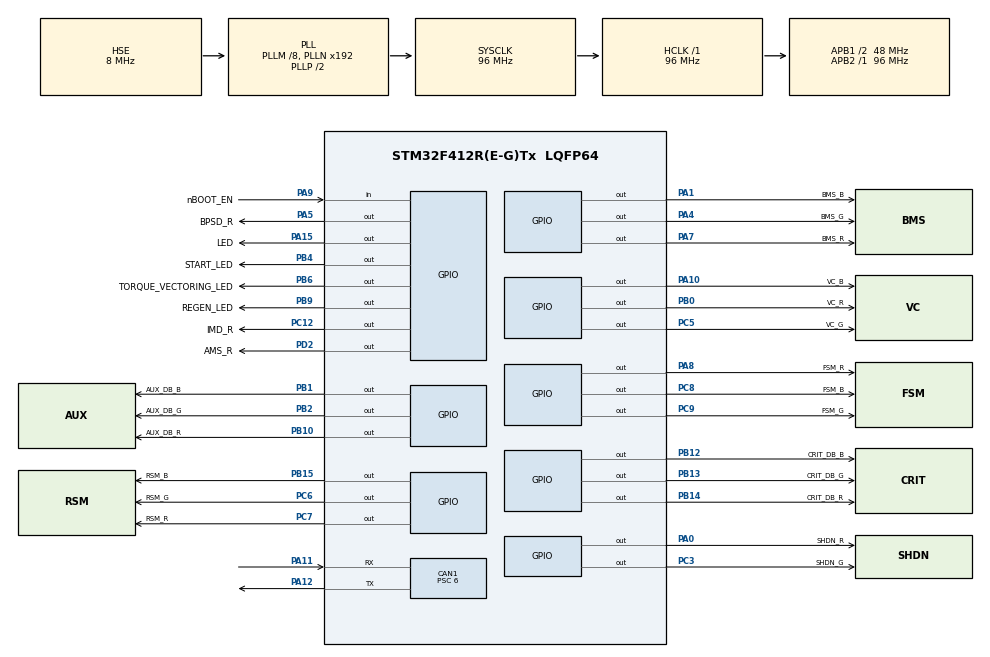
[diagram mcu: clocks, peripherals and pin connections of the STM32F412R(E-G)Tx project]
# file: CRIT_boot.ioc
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CAN1.ABOM=ENABLE
CAN1.BS1=CAN_BS1_13TQ
CAN1.BS2=CAN_BS2_2TQ
CAN1.CalculateBaudRate=500000
CAN1.CalculateTimeBit=2000
CAN1.CalculateTimeQuantum=125.0
CAN1.NART=ENABLE
CAN1.Prescaler=6
CAN1.RFLM=ENABLE
CAN1.SJW=CAN_SJW_4TQ
CAN1.TXFP=ENABLE
FREERTOS.Tasks01=interfaceTask,32,512,runInterfaceTask,Default,NULL,Static,interfaceTaskBuffer,interfaceTaskControlBlock;canTxTask,16,512,runCanTxTask,Default,NULL,Static,canTxTaskBuffer,canTxTaskControlBlock;tickTask,24,512,runTickTask,Default,NULL,Static,tickTaskBuffer,tickTaskControlBlock
FREERTOS.configUSE_NEWLIB_REENTRANT=1
Mcu.Family=STM32F4
Mcu.Name=STM32F412R(E-G)Tx
Mcu.Package=LQFP64
NVIC.CAN1_RX0_IRQn=true\:5\:0\:false\:false\:true\:true\:true\:true\:true
NVIC.CAN1_RX1_IRQn=true\:5\:0\:false\:false\:true\:true\:true\:true\:true
NVIC.PriorityGroup=NVIC_PRIORITYGROUP_4
NVIC.TIM6_IRQn=true\:15\:0\:false\:false\:true\:false\:false\:true\:true
NVIC.TimeBase=TIM6_IRQn
NVIC.TimeBaseIP=TIM6
PA0.GPIO_Label=SHDN_R
PA0.Signal=GPIO_Output
PA1.GPIO_Label=BMS_B
PA1.Signal=GPIO_Output
PA10.GPIO_Label=VC_B
PA10.Signal=GPIO_Output
PA11.Mode=CAN_Activate
PA11.Signal=CAN1_RX
PA12.Mode=CAN_Activate
PA12.Signal=CAN1_TX
PA13.Mode=Trace_Asynchronous_SW
PA13.Signal=SYS_JTMS-SWDIO
PA14.Mode=Trace_Asynchronous_SW
PA14.Signal=SYS_JTCK-SWCLK
PA15.GPIO_Label=LED
PA15.Signal=GPIO_Output
PA4.GPIO_Label=BMS_G
PA4.Signal=GPIO_Output
PA5.GPIO_Label=BPSD_R
PA5.Signal=GPIO_Output
PA7.GPIO_Label=BMS_R
PA7.Signal=GPIO_Output
PA8.GPIO_Label=FSM_R
PA8.Signal=GPIO_Output
PA9.GPIO_Label=nBOOT_EN
PA9.GPIO_PuPd=GPIO_PULLUP
PA9.Signal=GPIO_Input
PB0.GPIO_Label=VC_R
PB0.Signal=GPIO_Output
PB1.GPIO_Label=AUX_DB_B
PB1.Signal=GPIO_Output
PB10.GPIO_Label=AUX_DB_R
PB10.Signal=GPIO_Output
PB12.GPIO_Label=CRIT_DB_B
PB12.Signal=GPIO_Output
PB13.GPIO_Label=CRIT_DB_G
PB13.Signal=GPIO_Output
PB14.GPIO_Label=CRIT_DB_R
PB14.Signal=GPIO_Output
PB15.GPIO_Label=RSM_B
PB15.Signal=GPIO_Output
PB2.GPIO_Label=AUX_DB_G
PB2.Signal=GPIO_Output
PB3.Mode=Trace_Asynchronous_SW
PB3.Signal=SYS_JTDO-SWO
PB4.GPIO_Label=START_LED
PB4.Signal=GPIO_Output
PB6.GPIO_Label=TORQUE_VECTORING_LED
PB6.Signal=GPIO_Output
PB9.GPIO_Label=REGEN_LED
PB9.Signal=GPIO_Output
PC12.GPIO_Label=IMD_R
PC12.Signal=GPIO_Output
PC3.GPIO_Label=SHDN_G
PC3.Signal=GPIO_Output
PC5.GPIO_Label=VC_G
PC5.Signal=GPIO_Output
PC6.GPIO_Label=RSM_G
PC6.Signal=GPIO_Output
PC7.GPIO_Label=RSM_R
PC7.Signal=GPIO_Output
PC8.GPIO_Label=FSM_B
PC8.Signal=GPIO_Output
PC9.GPIO_Label=FSM_G
PC9.Signal=GPIO_Output
PD2.GPIO_Label=AMS_R
PD2.Signal=GPIO_Output
PH0\ -\ OSC_IN.Mode=HSE-External-Oscillator
PH0\ -\ OSC_IN.Signal=RCC_OSC_IN
PH1\ -\ OSC_OUT.Mode=HSE-External-Oscillator
PH1\ -\ OSC_OUT.Signal=RCC_OSC_OUT
ProjectManager.HeapSize=0x00
ProjectManager.StackSize=0x400
ProjectManager.TargetToolchain=STM32CubeIDE
RCC.AHBFreq_Value=96000000
RCC.APB1CLKDivider=RCC_HCLK_DIV2
RCC.APB1Freq_Value=48000000
RCC.APB1TimFreq_Value=96000000
RCC.APB2Freq_Value=96000000
RCC.APB2TimFreq_Value=96000000
RCC.CortexFreq_Value=96000000
RCC.HCLKFreq_Value=96000000
RCC.HSE_VALUE=8000000
RCC.PLLM=8
RCC.PLLSourceVirtual=RCC_PLLSOURCE_HSE
RCC.SYSCLKFreq_VALUE=96000000
RCC.SYSCLKSource=RCC_SYSCLKSOURCE_PLLCLK
RCC.USBFreq_Value=96000000
RCC.VCOOutputFreq_Value=192000000
VP_CRC_VS_CRC.Mode=CRC_Activate
VP_FREERTOS_VS_CMSIS_V2.Mode=CMSIS_V2
VP_SYS_VS_tim6.Mode=TIM6
board=custom

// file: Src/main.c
/* USER CODE BEGIN Header */
/**
 ******************************************************************************
 * @file           : main.c
 * @brief          : Main program body
 ******************************************************************************
 * @attention
 *
 * Copyright (c) 2023 STMicroelectronics.
 * All rights reserved.
 *
 * This software is licensed under terms that can be found in the LICENSE file
 * in the root directory of this software component.
 * If no LICENSE file comes with this software, it is provided AS-IS.
 *
 ******************************************************************************
 */
/* USER CODE END Header */
#include "main.h"
#include "cmsis_os.h"

/* USER CODE BEGIN Includes */
#include "bootloader.h"
#include "hw_can.h"
#include "hw_error.h"
#include "hw_utils.h"
#include "io_canQueue.h"

#include <assert.h>
/* USER CODE END Includes */

typedef StaticTask_t osStaticThreadDef_t;

CAN_HandleTypeDef hcan1;

CRC_HandleTypeDef hcrc;

/* Definitions for interfaceTask */
osThreadId_t         interfaceTaskHandle;
uint32_t             interfaceTaskBuffer[512];
osStaticThreadDef_t  interfaceTaskControlBlock;
const osThreadAttr_t interfaceTask_attributes = {
    .name       = "interfaceTask",
    .cb_mem     = &interfaceTaskControlBlock,
    .cb_size    = sizeof(interfaceTaskControlBlock),
    .stack_mem  = &interfaceTaskBuffer[0],
    .stack_size = sizeof(interfaceTaskBuffer),
    .priority   = (osPriority_t)osPriorityAboveNormal,
};
/* Definitions for canTxTask */
osThreadId_t         canTxTaskHandle;
uint32_t             canTxTaskBuffer[512];
osStaticThreadDef_t  canTxTaskControlBlock;
const osThreadAttr_t canTxTask_attributes = {
    .name       = "canTxTask",
    .cb_mem     = &canTxTaskControlBlock,
    .cb_size    = sizeof(canTxTaskControlBlock),
    .stack_mem  = &canTxTaskBuffer[0],
    .stack_size = sizeof(canTxTaskBuffer),
    .priority   = (osPriority_t)osPriorityBelowNormal,
};
/* Definitions for tickTask */
osThreadId_t         tickTaskHandle;
uint32_t             tickTaskBuffer[512];
osStaticThreadDef_t  tickTaskControlBlock;
const osThreadAttr_t tickTask_attributes = {
    .name       = "tickTask",
    .cb_mem     = &tickTaskControlBlock,
    .cb_size    = sizeof(tickTaskControlBlock),
    .stack_mem  = &tickTaskBuffer[0],
    .stack_size = sizeof(tickTaskBuffer),
    .priority   = (osPriority_t)osPriorityNormal,
};
/* USER CODE BEGIN PV */
CanHandle can = { .hcan = &hcan1, .bus_num = 1, .receive_callback = io_canQueue_pushRx };
/* USER CODE END PV */

void        SystemClock_Config(void);
static void MX_GPIO_Init(void);
static void MX_CAN1_Init(void);
static void MX_CRC_Init(void);
void        runInterfaceTask(void *argument);
void        runCanTxTask(void *argument);
void        runTickTask(void *argument);

int main(void)
{
    /* USER CODE BEGIN 1 */
    bootloader_preInit();
    /* USER CODE END 1 */

    /* MCU Configuration--------------------------------------------------------*/

    /* Reset of all peripherals, Initializes the Flash interface and the Systick. */
    HAL_Init();

    /* Configure the system clock */
    SystemClock_Config();

    /* Initialize all configured peripherals */
    MX_GPIO_Init();
    MX_CAN1_Init();
    MX_CRC_Init();
    /* USER CODE BEGIN 2 */
    bootloader_init();
    /* USER CODE END 2 */

    /* Init scheduler */
    osKernelInitialize();

    /* Create the thread(s) */
    /* creation of interfaceTask */
    interfaceTaskHandle = osThreadNew(runInterfaceTask, NULL, &interfaceTask_attributes);

    /* creation of canTxTask */
    canTxTaskHandle = osThreadNew(runCanTxTask, NULL, &canTxTask_attributes);

    /* creation of tickTask */
    tickTaskHandle = osThreadNew(runTickTask, NULL, &tickTask_attributes);

    /* Start scheduler */
    osKernelStart();

    /* We should never get here as control is now taken by the scheduler */
    /* Infinite loop */
    while (1)
    {

    }
}

void SystemClock_Config(void)
{
    RCC_OscInitTypeDef RCC_OscInitStruct = { 0 };
    RCC_ClkInitTypeDef RCC_ClkInitStruct = { 0 };

    /** Configure the main internal regulator output voltage
     */
    __HAL_RCC_PWR_CLK_ENABLE();
    __HAL_PWR_VOLTAGESCALING_CONFIG(PWR_REGULATOR_VOLTAGE_SCALE1);

    /** Initializes the RCC Oscillators according to the specified parameters
     * in the RCC_OscInitTypeDef structure.
     */
    RCC_OscInitStruct.OscillatorType = RCC_OSCILLATORTYPE_HSE;
    RCC_OscInitStruct.HSEState       = RCC_HSE_ON;
    RCC_OscInitStruct.PLL.PLLState   = RCC_PLL_ON;
    RCC_OscInitStruct.PLL.PLLSource  = RCC_PLLSOURCE_HSE;
    RCC_OscInitStruct.PLL.PLLM       = 8;
    RCC_OscInitStruct.PLL.PLLN       = 192;
    RCC_OscInitStruct.PLL.PLLP       = RCC_PLLP_DIV2;
    RCC_OscInitStruct.PLL.PLLQ       = 2;
    RCC_OscInitStruct.PLL.PLLR       = 2;
    if (HAL_RCC_OscConfig(&RCC_OscInitStruct) != HAL_OK)
    {
        Error_Handler();
    }

    /** Initializes the CPU, AHB and APB buses clocks
     */
    RCC_ClkInitStruct.ClockType = RCC_CLOCKTYPE_HCLK | RCC_CLOCKTYPE_SYSCLK | RCC_CLOCKTYPE_PCLK1 | RCC_CLOCKTYPE_PCLK2;
    RCC_ClkInitStruct.SYSCLKSource   = RCC_SYSCLKSOURCE_PLLCLK;
    RCC_ClkInitStruct.AHBCLKDivider  = RCC_SYSCLK_DIV1;
    RCC_ClkInitStruct.APB1CLKDivider = RCC_HCLK_DIV2;
    RCC_ClkInitStruct.APB2CLKDivider = RCC_HCLK_DIV1;

    if (HAL_RCC_ClockConfig(&RCC_ClkInitStruct, FLASH_LATENCY_3) != HAL_OK)
    {
        Error_Handler();
    }
}

static void MX_CAN1_Init(void)
{

    hcan1.Instance                  = CAN1;
    hcan1.Init.Prescaler            = 6;
    hcan1.Init.Mode                 = CAN_MODE_NORMAL;
    hcan1.Init.SyncJumpWidth        = CAN_SJW_4TQ;
    hcan1.Init.TimeSeg1             = CAN_BS1_13TQ;
    hcan1.Init.TimeSeg2             = CAN_BS2_2TQ;
    hcan1.Init.TimeTriggeredMode    = DISABLE;
    hcan1.Init.AutoBusOff           = ENABLE;
    hcan1.Init.AutoWakeUp           = DISABLE;
    hcan1.Init.AutoRetransmission   = ENABLE;
    hcan1.Init.ReceiveFifoLocked    = ENABLE;
    hcan1.Init.TransmitFifoPriority = ENABLE;
    if (HAL_CAN_Init(&hcan1) != HAL_OK)
    {
        Error_Handler();
    }
}

static void MX_CRC_Init(void)
{

    hcrc.Instance = CRC;
    if (HAL_CRC_Init(&hcrc) != HAL_OK)
    {
        Error_Handler();
    }
}

static void MX_GPIO_Init(void)
{
    GPIO_InitTypeDef GPIO_InitStruct = { 0 };

    /* GPIO Ports Clock Enable */
    __HAL_RCC_GPIOH_CLK_ENABLE();
    __HAL_RCC_GPIOC_CLK_ENABLE();
    __HAL_RCC_GPIOA_CLK_ENABLE();
    __HAL_RCC_GPIOB_CLK_ENABLE();
    __HAL_RCC_GPIOD_CLK_ENABLE();

    /*Configure GPIO pin Output Level */
    HAL_GPIO_WritePin(
        GPIOC, SHDN_G_Pin | VC_G_Pin | RSM_G_Pin | RSM_R_Pin | FSM_B_Pin | FSM_G_Pin | IMD_R_Pin, GPIO_PIN_RESET);

    /*Configure GPIO pin Output Level */
    HAL_GPIO_WritePin(
        GPIOA, SHDN_R_Pin | BMS_B_Pin | BMS_G_Pin | BPSD_R_Pin | BMS_R_Pin | FSM_R_Pin | VC_B_Pin | LED_Pin,
        GPIO_PIN_RESET);

    /*Configure GPIO pin Output Level */
    HAL_GPIO_WritePin(
        GPIOB,
        VC_R_Pin | AUX_DB_B_Pin | AUX_DB_G_Pin | AUX_DB_R_Pin | CRIT_DB_B_Pin | CRIT_DB_G_Pin | CRIT_DB_R_Pin |
            RSM_B_Pin | START_LED_Pin | TORQUE_VECTORING_LED_Pin | REGEN_LED_Pin,
        GPIO_PIN_RESET);

    /*Configure GPIO pin Output Level */
    HAL_GPIO_WritePin(AMS_R_GPIO_Port, AMS_R_Pin, GPIO_PIN_RESET);

    /*Configure GPIO pins : SHDN_G_Pin VC_G_Pin RSM_G_Pin RSM_R_Pin
                             FSM_B_Pin FSM_G_Pin IMD_R_Pin */
    GPIO_InitStruct.Pin   = SHDN_G_Pin | VC_G_Pin | RSM_G_Pin | RSM_R_Pin | FSM_B_Pin | FSM_G_Pin | IMD_R_Pin;
    GPIO_InitStruct.Mode  = GPIO_MODE_OUTPUT_PP;
    GPIO_InitStruct.Pull  = GPIO_NOPULL;
    GPIO_InitStruct.Speed = GPIO_SPEED_FREQ_LOW;
    HAL_GPIO_Init(GPIOC, &GPIO_InitStruct);

    /*Configure GPIO pins : SHDN_R_Pin BMS_B_Pin BMS_G_Pin BPSD_R_Pin
                             BMS_R_Pin FSM_R_Pin VC_B_Pin LED_Pin */
    GPIO_InitStruct.Pin  = SHDN_R_Pin | BMS_B_Pin | BMS_G_Pin | BPSD_R_Pin | BMS_R_Pin | FSM_R_Pin | VC_B_Pin | LED_Pin;
    GPIO_InitStruct.Mode = GPIO_MODE_OUTPUT_PP;
    GPIO_InitStruct.Pull = GPIO_NOPULL;
    GPIO_InitStruct.Speed = GPIO_SPEED_FREQ_LOW;
    HAL_GPIO_Init(GPIOA, &GPIO_InitStruct);

    /*Configure GPIO pins : VC_R_Pin AUX_DB_B_Pin AUX_DB_G_Pin AUX_DB_R_Pin
                             CRIT_DB_B_Pin CRIT_DB_G_Pin CRIT_DB_R_Pin RSM_B_Pin
                             START_LED_Pin TORQUE_VECTORING_LED_Pin REGEN_LED_Pin */
    GPIO_InitStruct.Pin = VC_R_Pin | AUX_DB_B_Pin | AUX_DB_G_Pin | AUX_DB_R_Pin | CRIT_DB_B_Pin | CRIT_DB_G_Pin |
                          CRIT_DB_R_Pin | RSM_B_Pin | START_LED_Pin | TORQUE_VECTORING_LED_Pin | REGEN_LED_Pin;
    GPIO_InitStruct.Mode  = GPIO_MODE_OUTPUT_PP;
    GPIO_InitStruct.Pull  = GPIO_NOPULL;
    GPIO_InitStruct.Speed = GPIO_SPEED_FREQ_LOW;
    HAL_GPIO_Init(GPIOB, &GPIO_InitStruct);

    /*Configure GPIO pin : nBOOT_EN_Pin */
    GPIO_InitStruct.Pin  = nBOOT_EN_Pin;
    GPIO_InitStruct.Mode = GPIO_MODE_INPUT;
    GPIO_InitStruct.Pull = GPIO_PULLUP;
    HAL_GPIO_Init(nBOOT_EN_GPIO_Port, &GPIO_InitStruct);

    /*Configure GPIO pin : AMS_R_Pin */
    GPIO_InitStruct.Pin   = AMS_R_Pin;
    GPIO_InitStruct.Mode  = GPIO_MODE_OUTPUT_PP;
    GPIO_InitStruct.Pull  = GPIO_NOPULL;
    GPIO_InitStruct.Speed = GPIO_SPEED_FREQ_LOW;
    HAL_GPIO_Init(AMS_R_GPIO_Port, &GPIO_InitStruct);

}

void runInterfaceTask(void *argument)
{
    /* USER CODE BEGIN 5 */
    bootloader_runInterfaceTask();
    /* USER CODE END 5 */
}

void runCanTxTask(void *argument)
{
    /* USER CODE BEGIN runCanTxTask */
    bootloader_runCanTxTask();
    /* USER CODE END runCanTxTask */
}

void runTickTask(void *argument)
{
    /* USER CODE BEGIN runTickTask */
    bootloader_runTickTask();
    /* USER CODE END runTickTask */
}

void HAL_TIM_PeriodElapsedCallback(TIM_HandleTypeDef *htim)
{
    if (htim->Instance == TIM6)
    {
        HAL_IncTick();
    }
}

void Error_Handler(void)
{
    __disable_irq();
    while (1)
    {
    }
}
